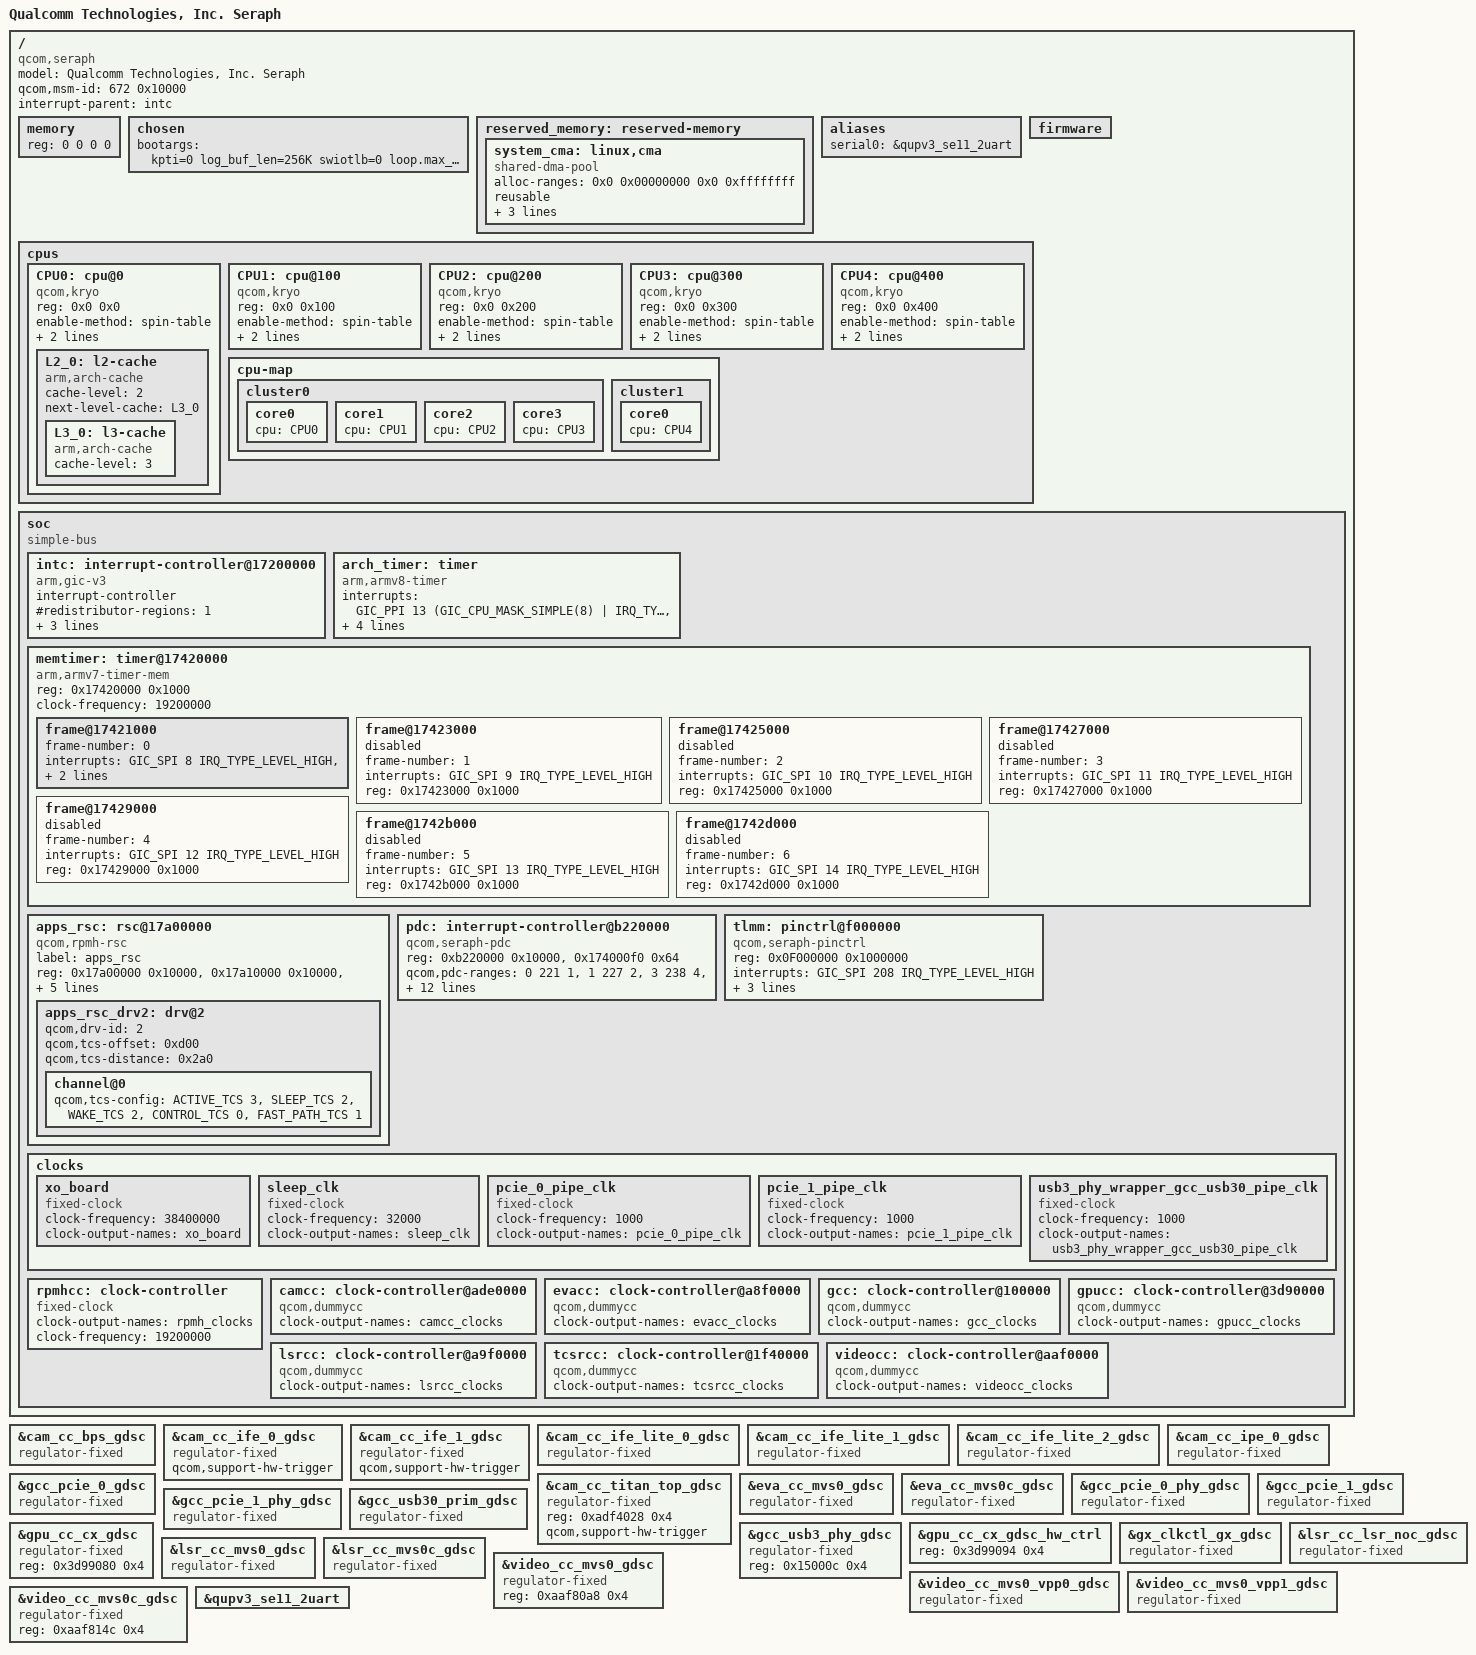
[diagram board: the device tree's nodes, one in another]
#include <dt-bindings/interrupt-controller/arm-gic.h>
#include <dt-bindings/soc/qcom,rpmh-rsc.h>
#include <dt-bindings/clock/qcom,rpmh.h>
#include <dt-bindings/clock/qcom,camcc-seraph.h>
#include <dt-bindings/clock/qcom,evacc-seraph.h>
#include <dt-bindings/clock/qcom,gcc-seraph.h>
#include <dt-bindings/clock/qcom,gpucc-seraph.h>
#include <dt-bindings/clock/qcom,lsrcc-seraph.h>
#include <dt-bindings/clock/qcom,tcsrcc-seraph.h>
#include <dt-bindings/clock/qcom,videocc-seraph.h>
#include <dt-bindings/regulator/qcom,rpmh-regulator-levels.h>

/ {
	model = "Qualcomm Technologies, Inc. Seraph";
	compatible = "qcom,seraph";
	qcom,msm-id = <672 0x10000>;
	interrupt-parent = <&intc>;

	#address-cells = <2>;
	#size-cells = <2>;
	memory { device_type = "memory"; reg = <0 0 0 0>; };

	chosen: chosen {
		bootargs = "kpti=0 log_buf_len=256K swiotlb=0 loop.max_part=7 loglevel=8";
	};

	reserved_memory: reserved-memory {};

	aliases {
		serial0 = &qupv3_se11_2uart;
	 };

	firmware: firmware {};

	cpus {
		#address-cells = <2>;
		#size-cells = <0>;

		CPU0: cpu@0 {
			device_type = "cpu";
			compatible = "qcom,kryo";
			reg = <0x0 0x0>;
			enable-method = "spin-table";
			cpu-release-addr = <0x0 0x90000000>;
			next-level-cache = <&L2_0>;
			L2_0: l2-cache {
				compatible = "arm,arch-cache";
				cache-level = <2>;
				next-level-cache = <&L3_0>;

				L3_0: l3-cache {
					compatible = "arm,arch-cache";
					cache-level = <3>;
				};
			};
		};

		CPU1: cpu@100 {
			device_type = "cpu";
			compatible = "qcom,kryo";
			reg = <0x0 0x100>;
			enable-method = "spin-table";
			cpu-release-addr = <0x0 0x90000000>;
			next-level-cache = <&L2_0>;
		};

		CPU2: cpu@200 {
			device_type = "cpu";
			compatible = "qcom,kryo";
			reg = <0x0 0x200>;
			enable-method = "spin-table";
			cpu-release-addr = <0x0 0x90000000>;
			next-level-cache = <&L2_0>;
		};

		CPU3: cpu@300 {
			device_type = "cpu";
			compatible = "qcom,kryo";
			reg = <0x0 0x300>;
			enable-method = "spin-table";
			cpu-release-addr = <0x0 0x90000000>;
			next-level-cache = <&L2_0>;
		};

		CPU4: cpu@400 {
			device_type = "cpu";
			compatible = "qcom,kryo";
			reg = <0x0 0x400>;
			enable-method = "spin-table";
			cpu-release-addr = <0x0 0x90000000>;
			next-level-cache = <&L2_0>;
		};

		cpu-map {
			cluster0 {
				core0 {
					cpu = <&CPU0>;
				};

				core1 {
					cpu = <&CPU1>;
				};

				core2 {
					cpu = <&CPU2>;
				};

				core3 {
					cpu = <&CPU3>;
				};
			};

			cluster1 {
				core0 {
					cpu = <&CPU4>;
				};
			};
		};
	};

	soc: soc { };

};

&soc {
	#address-cells = <1>;
	#size-cells = <1>;

	ranges = <0 0 0 0xffffffff>;
	compatible = "simple-bus";

	intc: interrupt-controller@17200000 {
		compatible = "arm,gic-v3";
		#interrupt-cells = <3>;
		interrupt-controller;
		#redistributor-regions = <1>;
		redistributor-stride = <0x0 0x20000>;
		reg = <0x17200000 0x10000>,       /* GICD */
		     <0x17260000 0xA0000>;       /* GICR * 5 */
		interrupts = <GIC_PPI 9 IRQ_TYPE_LEVEL_HIGH>;
	};

	arch_timer: timer {
		compatible = "arm,armv8-timer";
		interrupts = <GIC_PPI 13 (GIC_CPU_MASK_SIMPLE(8) | IRQ_TYPE_LEVEL_LOW)>,
			     <GIC_PPI 14 (GIC_CPU_MASK_SIMPLE(8) | IRQ_TYPE_LEVEL_LOW)>,
			     <GIC_PPI 11 (GIC_CPU_MASK_SIMPLE(8) | IRQ_TYPE_LEVEL_LOW)>,
			     <GIC_PPI 12 (GIC_CPU_MASK_SIMPLE(8) | IRQ_TYPE_LEVEL_LOW)>;
		clock-frequency = <19200000>;
	};

	memtimer: timer@17420000 {
		#address-cells = <1>;
		#size-cells = <1>;
		ranges;
		compatible = "arm,armv7-timer-mem";
		reg = <0x17420000 0x1000>;
		clock-frequency = <19200000>;

		frame@17421000 {
			frame-number = <0>;
			interrupts = <GIC_SPI 8 IRQ_TYPE_LEVEL_HIGH>,
				     <GIC_SPI 6 IRQ_TYPE_LEVEL_HIGH>;
			reg = <0x17421000 0x1000>,
			      <0x17422000 0x1000>;
		};

		frame@17423000 {
			frame-number = <1>;
			interrupts = <GIC_SPI 9 IRQ_TYPE_LEVEL_HIGH>;
			reg = <0x17423000 0x1000>;
			status = "disabled";
		};

		frame@17425000 {
			frame-number = <2>;
			interrupts = <GIC_SPI 10 IRQ_TYPE_LEVEL_HIGH>;
			reg = <0x17425000 0x1000>;
			status = "disabled";
		};

		frame@17427000 {
			frame-number = <3>;
			interrupts = <GIC_SPI 11 IRQ_TYPE_LEVEL_HIGH>;
			reg = <0x17427000 0x1000>;
			status = "disabled";
		};

		frame@17429000 {
			frame-number = <4>;
			interrupts = <GIC_SPI 12 IRQ_TYPE_LEVEL_HIGH>;
			reg = <0x17429000 0x1000>;
			status = "disabled";
		};

		frame@1742b000 {
			frame-number = <5>;
			interrupts = <GIC_SPI 13 IRQ_TYPE_LEVEL_HIGH>;
			reg = <0x1742b000 0x1000>;
			status = "disabled";
		};

		frame@1742d000 {
			frame-number = <6>;
			interrupts = <GIC_SPI 14 IRQ_TYPE_LEVEL_HIGH>;
			reg = <0x1742d000 0x1000>;
			status = "disabled";
		};
	};

	apps_rsc: rsc@17a00000 {
		label = "apps_rsc";
		compatible = "qcom,rpmh-rsc";
		reg = <0x17a00000 0x10000>,
		      <0x17a10000 0x10000>,
		      <0x17a20000 0x10000>;
		reg-names = "drv-0", "drv-1", "drv-2";
		qcom,drv-count = <3>;
		interrupts = <GIC_SPI 3 IRQ_TYPE_LEVEL_HIGH>,
			     <GIC_SPI 4 IRQ_TYPE_LEVEL_HIGH>,
			     <GIC_SPI 5 IRQ_TYPE_LEVEL_HIGH>;

		apps_rsc_drv2: drv@2 {
			qcom,drv-id = <2>;
			qcom,tcs-offset = <0xd00>;
			qcom,tcs-distance = <0x2a0>;
			channel@0 {
				qcom,tcs-config = <ACTIVE_TCS    3>,
						  <SLEEP_TCS     2>,
						  <WAKE_TCS      2>,
						  <CONTROL_TCS   0>,
						  <FAST_PATH_TCS 1>;
			};
		};
	};

	pdc: interrupt-controller@b220000 {
		compatible = "qcom,seraph-pdc", "qcom,pdc";
		reg = <0xb220000 0x10000>, <0x174000f0 0x64>;
		qcom,pdc-ranges = <0 221 1>, <1 227 2>, <3 238 4>,
				  <8 263 2>, <10 293 3>, <14 297 2>,
				  <16 348 2>, <18 351 3>, <22 355 2>,
				  <24 641 1>, <25 358 1>, <26 376 2>,
				  <28 443 1>, <30 242 1>, <31 296 1>,
				  <32 354 1>, <33 357 1>, <34 444 3>,
				  <37 472 1>, <40 447 1>, <41 461 1>,
				  <42 473 1>, <43 462 1>, <44 584 1>,
				  <45 586 1>, <47 607 2>, <49 642 1>,
				  <50 656 1>, <51 527 1>, <61 505 1>,
				  <62 605 1>, <63 372 2>, <65 378 1>,
				  <66 431 1>, <70 528 46>, <116 609 31>,
				  <147 63 1>, <148 716 12>, <160 251 5>,
				  <165 379 1>;
		#interrupt-cells = <2>;
		interrupt-parent = <&intc>;
		interrupt-controller;
	};

	tlmm: pinctrl@f000000 {
		compatible = "qcom,seraph-pinctrl";
		reg = <0x0F000000 0x1000000>;
		interrupts = <GIC_SPI 208 IRQ_TYPE_LEVEL_HIGH>;
		gpio-controller;
		#gpio-cells = <2>;
		interrupt-controller;
		#interrupt-cells = <2>;
		wakeup-parent = <&pdc>;
	};

	clocks {
		xo_board: xo_board {
			compatible = "fixed-clock";
			clock-frequency = <38400000>;
			clock-output-names = "xo_board";
			#clock-cells = <0>;
		};

		sleep_clk: sleep_clk {
			compatible = "fixed-clock";
			clock-frequency = <32000>;
			clock-output-names = "sleep_clk";
			#clock-cells = <0>;
		};

		pcie_0_pipe_clk: pcie_0_pipe_clk {
			compatible = "fixed-clock";
			clock-frequency = <1000>;
			clock-output-names = "pcie_0_pipe_clk";
			#clock-cells = <0>;
		};

		pcie_1_pipe_clk: pcie_1_pipe_clk {
			compatible = "fixed-clock";
			clock-frequency = <1000>;
			clock-output-names = "pcie_1_pipe_clk";
			#clock-cells = <0>;
		};

		usb3_phy_wrapper_gcc_usb30_pipe_clk: usb3_phy_wrapper_gcc_usb30_pipe_clk {
			compatible = "fixed-clock";
			clock-frequency = <1000>;
			clock-output-names = "usb3_phy_wrapper_gcc_usb30_pipe_clk";
			#clock-cells = <0>;
		};
	};

	rpmhcc: clock-controller {
		compatible = "fixed-clock";
		clock-output-names = "rpmh_clocks";
		clock-frequency = <19200000>;
		#clock-cells = <1>;
	};

	camcc: clock-controller@ade0000 {
		compatible = "qcom,dummycc";
		clock-output-names = "camcc_clocks";
		#clock-cells = <1>;
		#reset-cells = <1>;
	};

	evacc: clock-controller@a8f0000 {
		compatible = "qcom,dummycc";
		clock-output-names = "evacc_clocks";
		#clock-cells = <1>;
		#reset-cells = <1>;
	};

	gcc: clock-controller@100000 {
		compatible = "qcom,dummycc";
		clock-output-names = "gcc_clocks";
		#clock-cells = <1>;
		#reset-cells = <1>;
	};

	gpucc: clock-controller@3d90000 {
		compatible = "qcom,dummycc";
		clock-output-names = "gpucc_clocks";
		#clock-cells = <1>;
		#reset-cells = <1>;
	};

	lsrcc: clock-controller@a9f0000 {
		compatible = "qcom,dummycc";
		clock-output-names = "lsrcc_clocks";
		#clock-cells = <1>;
		#reset-cells = <1>;
	};

	tcsrcc: clock-controller@1f40000 {
		compatible = "qcom,dummycc";
		clock-output-names = "tcsrcc_clocks";
		#clock-cells = <1>;
		#reset-cells = <1>;
	};

	videocc: clock-controller@aaf0000 {
		compatible = "qcom,dummycc";
		clock-output-names = "videocc_clocks";
		#clock-cells = <1>;
		#reset-cells = <1>;
	};
};

#include "pineapple-gdsc.dtsi"

&cam_cc_bps_gdsc {
	compatible = "regulator-fixed";
	status = "ok";
};

&cam_cc_ife_0_gdsc {
	compatible = "regulator-fixed";
	qcom,support-hw-trigger;
	status = "ok";
};

&cam_cc_ife_1_gdsc {
	compatible = "regulator-fixed";
	qcom,support-hw-trigger;
	status = "ok";
};

&cam_cc_ife_lite_0_gdsc {
	compatible = "regulator-fixed";
	status = "ok";
};

&cam_cc_ife_lite_1_gdsc {
	compatible = "regulator-fixed";
	status = "ok";
};

&cam_cc_ife_lite_2_gdsc {
	compatible = "regulator-fixed";
	status = "ok";
};

&cam_cc_ipe_0_gdsc {
	compatible = "regulator-fixed";
	status = "ok";
};

&cam_cc_titan_top_gdsc {
	compatible = "regulator-fixed";
	reg = <0xadf4028 0x4>;
	qcom,support-hw-trigger;
	status = "ok";
};

&eva_cc_mvs0_gdsc {
	compatible = "regulator-fixed";
	status = "ok";
};

&eva_cc_mvs0c_gdsc {
	compatible = "regulator-fixed";
	status = "ok";
};

&gcc_pcie_0_gdsc {
	compatible = "regulator-fixed";
	status = "ok";
};

&gcc_pcie_0_phy_gdsc {
	compatible = "regulator-fixed";
	status = "ok";
};

&gcc_pcie_1_gdsc {
	compatible = "regulator-fixed";
	status = "ok";
};

&gcc_pcie_1_phy_gdsc {
	compatible = "regulator-fixed";
	status = "ok";
};

&gcc_usb30_prim_gdsc {
	compatible = "regulator-fixed";
	status = "ok";
};

&gcc_usb3_phy_gdsc {
	compatible = "regulator-fixed";
	reg = <0x15000c 0x4>;
	status = "ok";
};

&gpu_cc_cx_gdsc_hw_ctrl {
	reg = <0x3d99094 0x4>;
};

&gpu_cc_cx_gdsc {
	compatible = "regulator-fixed";
	reg = <0x3d99080 0x4>;
	status = "ok";
};

&gx_clkctl_gx_gdsc {
	compatible = "regulator-fixed";
	status = "ok";
};

&lsr_cc_lsr_noc_gdsc {
	compatible = "regulator-fixed";
	status = "ok";
};

&lsr_cc_mvs0_gdsc {
	compatible = "regulator-fixed";
	status = "ok";
};

&lsr_cc_mvs0c_gdsc {
	compatible = "regulator-fixed";
	status = "ok";
};

&video_cc_mvs0_gdsc {
	compatible = "regulator-fixed";
	reg = <0xaaf80a8 0x4>;
	status = "ok";
};

&video_cc_mvs0_vpp0_gdsc {
	compatible = "regulator-fixed";
	status = "ok";
};

&video_cc_mvs0_vpp1_gdsc {
	compatible = "regulator-fixed";
	status = "ok";
};

&video_cc_mvs0c_gdsc {
	compatible = "regulator-fixed";
	reg = <0xaaf814c 0x4>;
	status = "ok";
};

#include "seraph-pinctrl.dtsi"
#include "seraph-qupv3.dtsi"

&qupv3_se11_2uart {
	status = "ok";
};

#include "seraph-stub-regulators.dtsi"

&reserved_memory {
	#address-cells = <2>;
	#size-cells = <2>;
	ranges;

	/* global autoconfigured region for contiguous allocations */
	system_cma: linux,cma {
		compatible = "shared-dma-pool";
		alloc-ranges = <0x0 0x00000000 0x0 0xffffffff>;
		reusable;
		alignment = <0x0 0x400000>;
		size = <0x0 0x2000000>;
		linux,cma-default;
	};
};

#include "seraph-reserved-memory.dtsi"
#include "seraph-dma-heaps.dtsi"
#include "msm-arm-smmu-seraph.dtsi"
